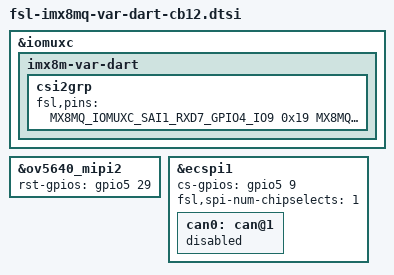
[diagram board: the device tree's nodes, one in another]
&iomuxc {
	imx8m-var-dart {
		csi2grp {
			fsl,pins = <
				MX8MQ_IOMUXC_SAI1_RXD7_GPIO4_IO9		0x19
				MX8MQ_IOMUXC_UART4_TXD_GPIO5_IO29		0x19
			>;
		};
	};
};

&ov5640_mipi2 {
	rst-gpios = <&gpio5 29 GPIO_ACTIVE_HIGH>;
};

&ecspi1 {
	cs-gpios = <&gpio5 9 0>;
	fsl,spi-num-chipselects = <1>;

	can0: can@1 {
		status = "disabled";
	};
};
